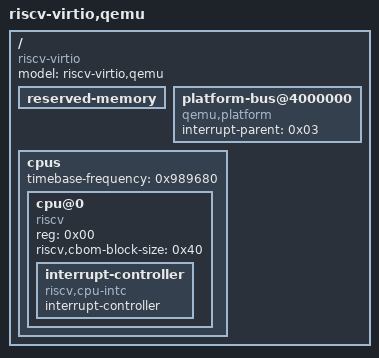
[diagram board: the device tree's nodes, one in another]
// Copyright 2023 Andrew Oates.  All Rights Reserved.
//
// Licensed under the Apache License, Version 2.0 (the "License");
// you may not use this file except in compliance with the License.
// You may obtain a copy of the License at
//
//     http://www.apache.org/licenses/LICENSE-2.0
//
// Unless required by applicable law or agreed to in writing, software
// distributed under the License is distributed on an "AS IS" BASIS,
// WITHOUT WARRANTIES OR CONDITIONS OF ANY KIND, either express or implied.
// See the License for the specific language governing permissions and
// limitations under the License.

/dts-v1/;

/ {
	#address-cells = <0x02>;
	#size-cells = <0x02>;
	compatible = "riscv-virtio";
	model = "riscv-virtio,qemu";

	reserved-memory {
		#address-cells = <0x02>;
		#size-cells = <0x02>;
		ranges;
	};

	platform-bus@4000000 {
		interrupt-parent = <0x03>;
		ranges = <0x00 0x00 0x4000000 0x2000000>;
		#address-cells = <0x01>;
		#size-cells = <0x01>;
		compatible = "qemu,platform\0simple-bus";
	};

	cpus {
		#address-cells = <0x01>;
		#size-cells = <0x00>;
		timebase-frequency = <0x989680>;

		cpu@0 {
			phandle = <0x01>;
			reg = <0x00>;
			compatible = "riscv";
			riscv,cbom-block-size = <0x40>;

			interrupt-controller {
				#interrupt-cells = <0x01>;
				interrupt-controller;
				compatible = "riscv,cpu-intc";
				phandle = <0x02>;
			};
		};
	};
};
